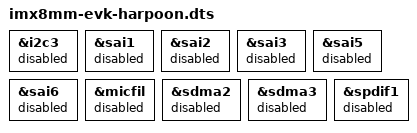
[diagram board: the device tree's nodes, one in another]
// SPDX-License-Identifier: (GPL-2.0+ OR MIT)
/*
 * Copyright 2021-2023, 2025 NXP
 */

#include "imx8mm-evk-root.dts"
#include "imx8m-rpmsg-ca53.dtsi"

&i2c3 {
	status = "disabled";
};

/* Disable the whole Audio system for Linux and give full ownership to RTOS. */
&sai1 {
	status = "disabled";
};

&sai2 {
	status = "disabled";
};

&sai3 {
	status = "disabled";
};

&sai5 {
	status = "disabled";
};

&sai6 {
	status = "disabled";
};

&micfil {
	status = "disabled";
};

&sdma2 {
	status = "disabled";
};

&sdma3 {
	status = "disabled";
};

&spdif1 {
	status = "disabled";
};
